# slm32x030 register map
Vendor: Keil; File version: 1.0.1
CPU: CM0 r2p1, little endian, no MPU, no FPU, 4 interrupt priority bits
Registers are 32-bit, read-write, reset 0x0 unless marked. A register's access mark holds for its fields unless they carry their own. Offsets are from the block's base; [hi:lo] are bit positions.

## IWDG — Independent watchdog(IWDG)
Base 0x40003000
0x00 KR wo — IWDG_KR
  [15:0] KEY — Later Add Description
0x04 PR — IWDG_PR
  [2:0] PR — Later Add Description
0x08 RLR — IWDG_RLR
  [11:0] RL — Later Add Description
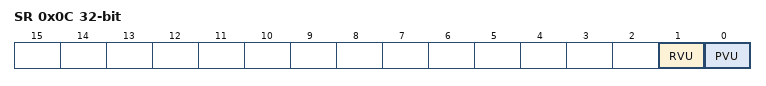
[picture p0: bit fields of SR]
0x0C SR access not given — IWDG_SR
  [1] RVU — Later Add Description
  [0] PVU — Later Add Description

## WWDG — Window Watchdog(WWDG)
Base 0x40002C00
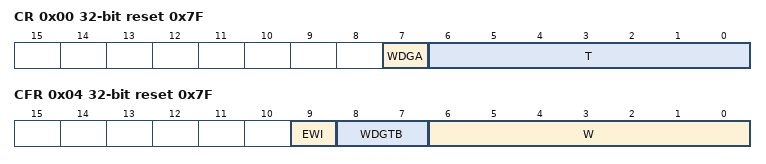
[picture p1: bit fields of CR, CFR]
0x00 CR access not given reset 0x7F — WWDG_CR
  [7] WDGA — Later Add Description
  [6:0] T rw — Later Add Description
0x04 CFR reset 0x7F — WWDG_CFR
  [9] EWI — Later Add Description
  [8:7] WDGTB — Later Add Description
  [6:0] W — Later Add Description
0x08 SR access not given — WWDG_SR
  [0] EWIF — Later Add Description

## SPI1 — Serial Peripheral Interface(SPI)
Base 0x40013000
Same registers: SPI2 0x40003800
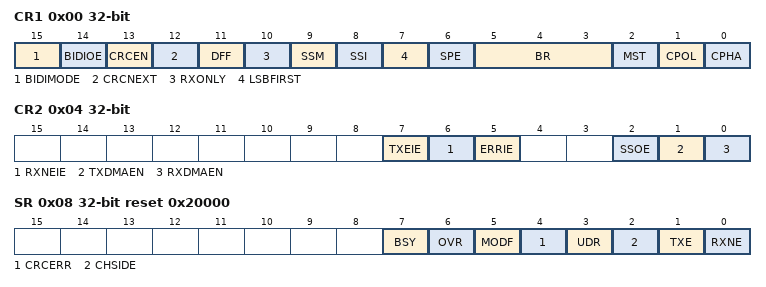
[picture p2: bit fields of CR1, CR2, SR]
0x00 CR1 — SPI_CR1
  [15] BIDIMODE — Later Add Description
  [14] BIDIOE — Later Add Description
  [13] CRCEN — Later Add Description
  [12] CRCNEXT — Later Add Description
  [11] DFF — Later Add Description
  [10] RXONLY — Later Add Description
  [9] SSM — Later Add Description
  [8] SSI — Later Add Description
  [7] LSBFIRST — Later Add Description
  [6] SPE — Later Add Description
  [5:3] BR — Later Add Description
  [2] MST — Later Add Description
  [1] CPOL — Later Add Description
  [0] CPHA — Later Add Description
0x04 CR2 — SPI_CR2
  [7] TXEIE — Later Add Description
  [6] RXNEIE — Later Add Description
  [5] ERRIE — Later Add Description
  [2] SSOE — Later Add Description
  [1] TXDMAEN — Later Add Description
  [0] RXDMAEN — Later Add Description
0x08 SR reset 0x20000 — SPI_SR
  [7] BSY — Later Add Description
  [6] OVR — Later Add Description
  [5] MODF — Later Add Description
  [4] CRCERR — Later Add Description
  [3] UDR — Later Add Description
  [2] CHSIDE — Later Add Description
  [1] TXE — Later Add Description
  [0] RXNE — Later Add Description
0x0C DR — SPI_DR
  [15:0] DR — Later Add Description
0x10 CRCPR reset 0x70000 — SPI_CRCPR
  [15:0] CRCPOLY — Later Add Description
0x14 RXCRCR — SPI_RXCRCR
  [15:0] RXCRC — Later Add Description
0x18 TXCRCR — SPI_TXCRCR
  [15:0] TXCRC — Later Add Description

## USART1 — Universal synchronous asynchronous transceiver(USART)
Base 0x40013800
Same registers: USART2 0x40004400
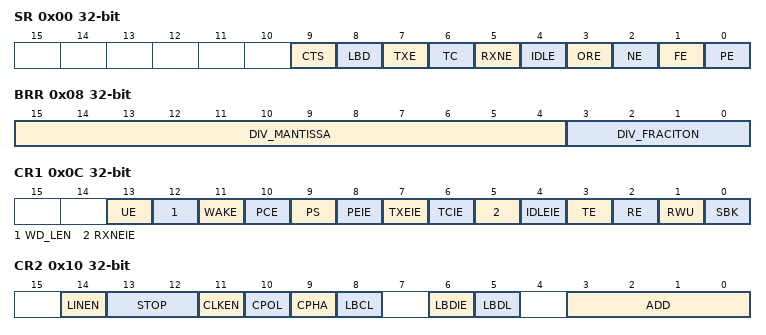
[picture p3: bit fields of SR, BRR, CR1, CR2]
0x00 SR access not given — USART_SR
  [9] CTS — Later Add Description
  [8] LBD — Later Add Description
  [7] TXE — Later Add Description
  [6] TC — Later Add Description
  [5] RXNE — Later Add Description
  [4] IDLE ro — Later Add Description
  [3] ORE ro — Later Add Description
  [2] NE ro — Later Add Description
  [1] FE ro — Later Add Description
  [0] PE — Later Add Description
0x04 DR access not given — USART_DR
  [8:0] DR — Later Add Description
0x08 BRR access not given — USART_BRR
  [15:4] DIV_MANTISSA — Later Add Description
  [3:0] DIV_FRACITON — Later Add Description
0x0C CR1 access not given — USART_CR1
  [13] UE rw — Later Add Description
  [12] WD_LEN rw — Later Add Description
  [11] WAKE rw — Later Add Description
  [10] PCE rw — Later Add Description
  [9] PS rw — Later Add Description
  [8] PEIE rw — Later Add Description
  [7] TXEIE rw — Later Add Description
  [6] TCIE rw — Later Add Description
  [5] RXNEIE rw — Later Add Description
  [4] IDLEIE rw — Later Add Description
  [3] TE — Later Add Description
  [2] RE rw — Later Add Description
  [1] RWU rw — Later Add Description
  [0] SBK rw — Later Add Description
0x10 CR2 — USART_CR2
  [14] LINEN — Later Add Description
  [13:12] STOP — Later Add Description
  [11] CLKEN — Later Add Description
  [10] CPOL — Later Add Description
  [9] CPHA — Later Add Description
  [8] LBCL — Later Add Description
  [6] LBDIE — Later Add Description
  [5] LBDL — Later Add Description
  [3:0] ADD — Later Add Description
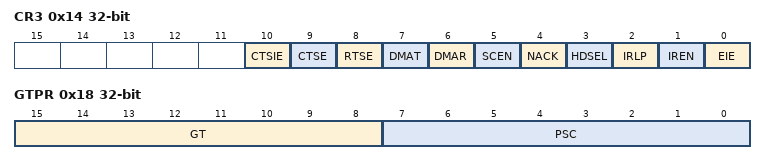
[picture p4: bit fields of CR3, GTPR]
0x14 CR3 — USART_CR3
  [10] CTSIE — Later Add Description
  [9] CTSE — Later Add Description
  [8] RTSE — Later Add Description
  [7] DMAT — Later Add Description
  [6] DMAR — Later Add Description
  [5] SCEN — Later Add Description
  [4] NACK — Later Add Description
  [3] HDSEL — Later Add Description
  [2] IRLP — Later Add Description
  [1] IREN — Later Add Description
  [0] EIE — Later Add Description
0x18 GTPR access not given — USART_GTPR
  [15:8] GT — Later Add Description
  [7:0] PSC — Later Add Description
